# AT32A403A register map
Vendor: Keil; Series: AT32A403A; File version: 1.0
CPU: CM4 r0p1, little endian, no MPU, FPU, 4 interrupt priority bits
Registers are 32-bit, read-write, reset 0x0 unless marked. A register's access mark holds for its fields unless they carry their own. Offsets are from the block's base; [hi:lo] are bit positions; {n}, {i} and the like mark numbered series.

## IOMUX — IO MUX function
Base 0x40010000
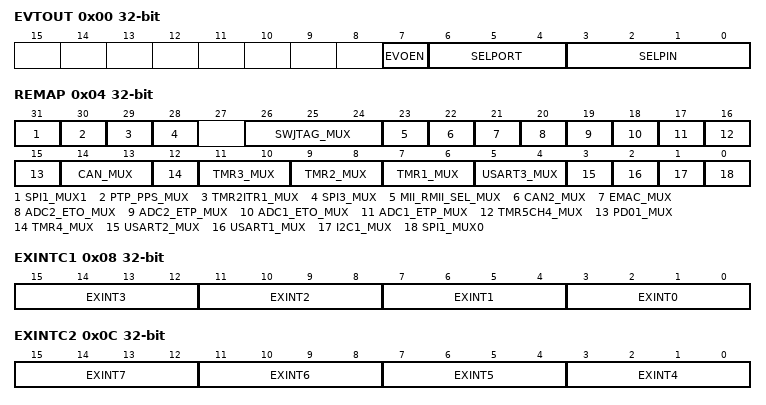
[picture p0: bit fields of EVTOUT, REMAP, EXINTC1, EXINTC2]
0x00 EVTOUT — Event output register (IOMUX_EVTOUT)
  [7] EVOEN — Event output enable
    0=Disable; 1=Enable
  [6:4] SELPORT — Select port
    0=GPIOA; 1=GPIOB; 2=GPIOC; 3=GPIOD; 5=GPIOE
  [3:0] SELPIN — Select pin
0x04 REMAP — IO MUX remap register (IOMUX_REMAP)
  [31] SPI1_MUX1 — SPI1 muxing bit1
  [30] PTP_PPS_MUX — PTP_PPS muxing
  [29] TMR2ITR1_MUX — TMR2 internal trigger 1 muxing
  [28] SPI3_MUX — SPI3 muxing
  [26:24] SWJTAG_MUX — SWD JTAG muxing
  [23] MII_RMII_SEL_MUX — MII_RMII select muxing
  [22] CAN2_MUX — CAN2 muxing
  [21] EMAC_MUX — Ethernet MAC muxing
  [20] ADC2_ETO_MUX — ADC2 external trigger ordinary conversion muxing
  [19] ADC2_ETP_MUX — ADC2 external trigger preempted conversion muxing
  [18] ADC1_ETO_MUX — ADC1 external trigger ordinary conversion muxing
  [17] ADC1_ETP_MUX — ADC1 external trigger preempted conversion muxing
  [16] TMR5CH4_MUX — TMR5 channel4 internal muxing
  [15] PD01_MUX — PD0/PD1 muxing on OSCIN/OSCOUT
  [14:13] CAN_MUX — CAN1 muxing
  [12] TMR4_MUX — TMR4 muxing
  [11:10] TMR3_MUX — TMR3 muxing
  [9:8] TMR2_MUX — TMR2 muxing
  [7:6] TMR1_MUX — TMR1 muxing
  [5:4] USART3_MUX — USART3 muxing
  [3] USART2_MUX — USART2 muxing
  [2] USART1_MUX — USART1 muxing
  [1] I2C1_MUX — I2C1 muxing
  [0] SPI1_MUX0 — SPI1 muxing bit0
0x08 EXINTC1 — External interrupt configuration register 1 (IOMUX_EXINTC1)
  [4n+3:4n] EXINT{n} (n=0..3) — Configure EXINT{n} source
0x0C EXINTC2 — External interrupt configuration register 2 (IOMUX_EXINTC2)
  [4n-13:4n-16] EXINT{n} (n=4..7) — Configure EXINT{n} source
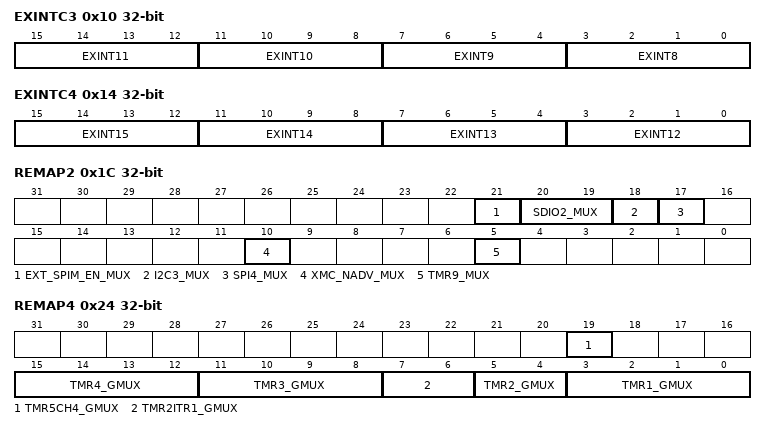
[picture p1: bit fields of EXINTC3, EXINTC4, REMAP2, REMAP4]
0x10 EXINTC3 — External interrupt configuration register 3 (IOMUX_EXINTC3)
  [4n-29:4n-32] EXINT{n} (n=8..11) — Configure EXINT{n} source
0x14 EXINTC4 — External interrupt configuration register 4 (IOMUX_EXINTC4)
  [4n-45:4n-48] EXINT{n} (n=12..15) — Configure EXINT{n} source
0x1C REMAP2 — IO MUX remap register 2 (IOMUX_REMAP2)
  [21] EXT_SPIM_EN_MUX — SPIM enable muxing
  [20:19] SDIO2_MUX — SDIO2 muxing
  [18] I2C3_MUX — I2C3 muxing
  [17] SPI4_MUX — SPI4 muxing
  [10] XMC_NADV_MUX — NADV connect/disconnect
  [5] TMR9_MUX — TMR9 muxing
0x20 REMAP3 — IO MUX remap register 3 (IOMUX_REMAP3)
  [3:0] TMR9_GMUX — TMR9 muxing
0x24 REMAP4 — IO MUX remap register 4 (IOMUX_REMAP4)
  [19] TMR5CH4_GMUX — TMR5 channel4 internal muxing
  [15:12] TMR4_GMUX — TMR4 muxing
  [11:8] TMR3_GMUX — TMR3 muxing
  [7:6] TMR2ITR1_GMUX — TMR2 internal trigger 1 muxing
  [5:4] TMR2_GMUX — TMR2 muxing
  [3:0] TMR1_GMUX — TMR1 muxing
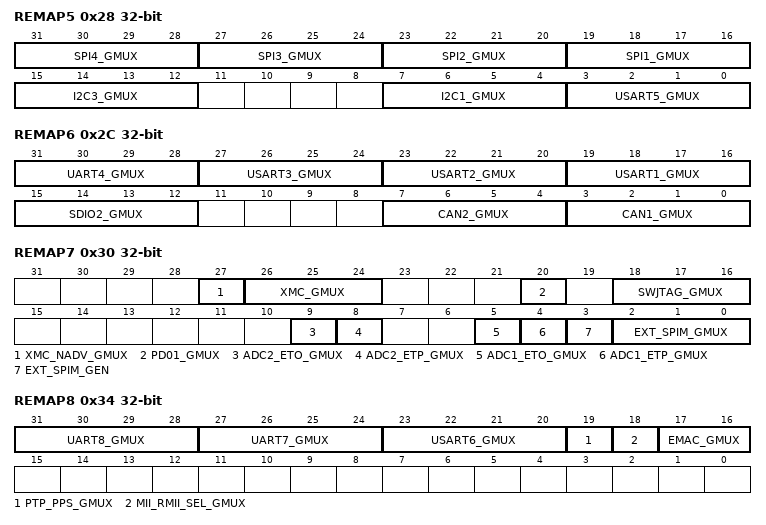
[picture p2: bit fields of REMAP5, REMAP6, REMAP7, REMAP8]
0x28 REMAP5 — IO MUX remap register 5 (IOMUX_REMAP5)
  [4n+15:4n+12] SPI{n}_GMUX (n=1..4) — SPI{n} muxing
  [15:12] I2C3_GMUX — I2C3 muxing
  [7:4] I2C1_GMUX — I2C1 muxing
  [3:0] USART5_GMUX — USART5 muxing
0x2C REMAP6 — IO MUX remap register 6 (IOMUX_REMAP6)
  [31:28] UART4_GMUX — UART4 muxing
  [27:24] USART3_GMUX — USART3 muxing
  [23:20] USART2_GMUX — USART2 muxing
  [19:16] USART1_GMUX — USART1 muxing
  [15:12] SDIO2_GMUX — SDIO2 muxing
  [7:4] CAN2_GMUX — CAN2 muxing
  [3:0] CAN1_GMUX — CAN1 muxing
0x30 REMAP7 — IO MUX remap register 7 (IOMUX_REMAP7)
  [27] XMC_NADV_GMUX — XMC_NADV muxing
  [26:24] XMC_GMUX — XMC muxing
  [20] PD01_GMUX — PortD0/PortD1 mappingon OSC_IN/OSC_OUT
  [18:16] SWJTAG_GMUX — Serial wire JTAG muxing
  [9] ADC2_ETO_GMUX — ADC2 external trigger ordinary conversion muxing
  [8] ADC2_ETP_GMUX — ADC2 external trigger preempted conversion muxing
  [5] ADC1_ETO_GMUX — ADC1 external trigger ordinary conversion muxing
  [4] ADC1_ETP_GMUX — ADC1 external trigger preempted conversion muxing
  [3] EXT_SPIM_GEN — SPIM enable
  [2:0] EXT_SPIM_GMUX — SPIM muxing
0x34 REMAP8 — IO MUX remap register 8 (IOMUX_REMAP8)
  [31:28] UART8_GMUX — UART8 muxing
  [27:24] UART7_GMUX — UART7 muxing
  [23:20] USART6_GMUX — USART6 muxing
  [19] PTP_PPS_GMUX — PTP_PPS muxing
  [18] MII_RMII_SEL_GMUX — MII_RMII select muxing
  [17:16] EMAC_GMUX — Ethernet MAC muxing
